# max32670 register map
Vendor: Maxim-Integrated; Series: ARMCM4; File version: 1.1
CPU: CM4 r2p1, little endian, MPU, FPU, 3 interrupt priority bits
Registers are 32-bit, read-write, reset 0x0 unless marked. A register's access mark holds for its fields unless they carry their own. Offsets are from the block's base; [hi:lo] are bit positions.

## I2S — Inter-IC Sound Interface.
Base 0x40060000
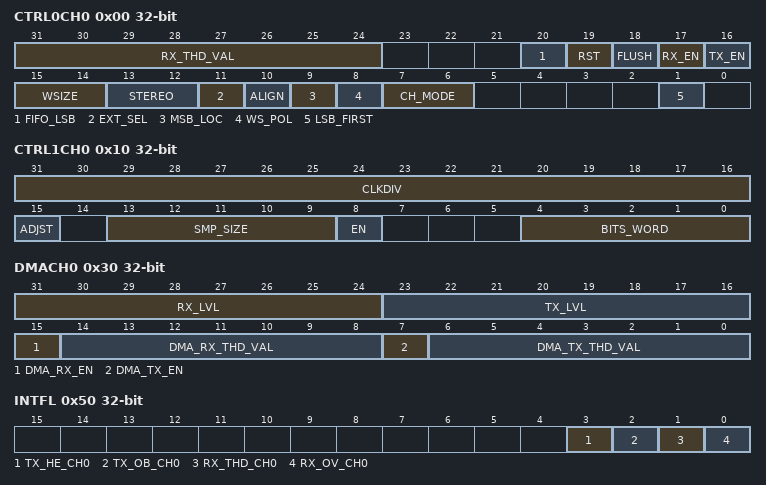
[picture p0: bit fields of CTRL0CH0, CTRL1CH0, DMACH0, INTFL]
0x00 CTRL0CH0 — Global mode channel.
  [31:24] RX_THD_VAL — depth of receive FIFO for threshold interrupt generation.
  [20] FIFO_LSB — Bit Field Control.
  [19] RST — Write 1 to reset channel.
  [18] FLUSH — Flushes the TX/RX FIFO buffer.
  [17] RX_EN — RX channel enable.
  [16] TX_EN — TX channel enable.
  [15:14] WSIZE — Data size when write to FIFO.
  [13:12] STEREO ro — Stereo mode of I2S.
  [11] EXT_SEL — External SCK/WS selection.
  [10] ALIGN ro — Align to MSB or LSB.
  [9] MSB_LOC ro — MSB location.
  [8] WS_POL — WS polarity select.
  [7:6] CH_MODE — SCK Select.
  [1] LSB_FIRST — LSB Transmit Receive First.
0x10 CTRL1CH0 — Local channel Setup.
  [31:16] CLKDIV — I2S clock frequency divisor.
  [15] ADJST — LSB/MSB Justify.
  [13:9] SMP_SIZE — I2S sample size length.
  [8] EN — I2S clock enable.
  [4:0] BITS_WORD — I2S word length.
0x30 DMACH0 — DMA Control.
  [31:24] RX_LVL — Number of data word in the RX FIFO.
  [23:16] TX_LVL — Number of data word in the TX FIFO.
  [15] DMA_RX_EN — RX DMA channel enable.
  [14:8] DMA_RX_THD_VAL — RX FIFO Level DMA Trigger.
  [7] DMA_TX_EN — TX DMA channel enable.
  [6:0] DMA_TX_THD_VAL — TX FIFO Level DMA Trigger.
0x40 FIFOCH0 — I2S Fifo.
  [31:0] DATA — Load/unload location for TX and RX FIFO buffers.
0x50 INTFL — ISR Status.
  [3] TX_HE_CH0 — Status for interrupt when TX FIFO is half empty.
  [2] TX_OB_CH0 — Status for interrupt when TX FIFO has only one byte remaining.
  [1] RX_THD_CH0 — Status for interrupt when RX FIFO reaches the number of bytes configured by the RXTHD field.
  [0] RX_OV_CH0 — Status for RX FIFO Overrun interrupt.
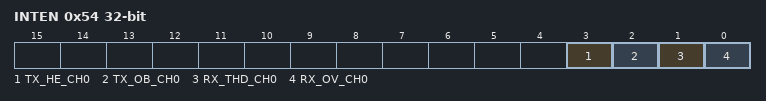
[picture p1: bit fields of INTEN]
0x54 INTEN — Interrupt Enable.
  [3] TX_HE_CH0 — Enable for interrupt when TX FIFO is half empty.
  [2] TX_OB_CH0 — Enable for interrupt when TX FIFO has only one byte remaining.
  [1] RX_THD_CH0 — Enable for interrupt when RX FIFO reaches the number of bytes configured by the RXTHD field.
  [0] RX_OV_CH0 — Enable for RX FIFO Overrun interrupt.
0x58 EXTSETUP — Ext Control.
  [4:0] EXT_BITS_WORD — Word Length for ch_mode.

## ICC0 — Instruction Cache Controller Registers
Base 0x4002A000
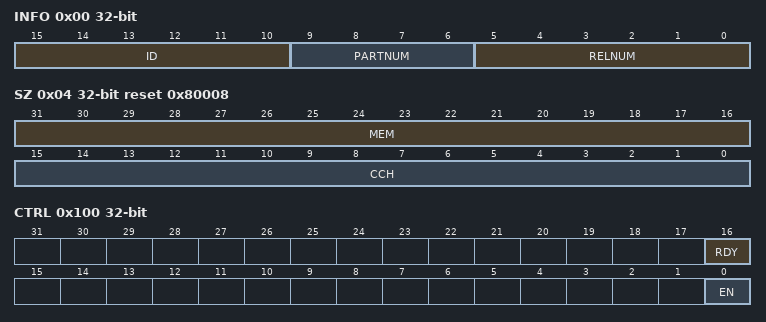
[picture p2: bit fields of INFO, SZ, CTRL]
0x00 INFO ro — Cache ID Register.
  [15:10] ID — Cache ID. This field reflects the value of the C_ID_CACHEID configuration parameter.
  [9:6] PARTNUM — Part Number. This field reflects the value of C_ID_PART_NUMBER configuration parameter.
  [5:0] RELNUM — Release Number. Identifies the RTL release version.
0x04 SZ ro reset 0x80008 — Memory Configuration Register.
  [31:16] MEM — Main Memory Size. Indicates the total size, in units of 128 Kbytes, of code memory accessible to the cache controller.
  [15:0] CCH — Cache Size. Indicates total size in Kbytes of cache.
0x100 CTRL — Cache Control and Status Register.
  [16] RDY ro — Cache Ready flag. Cleared by hardware when at any time the cache as a whole is invalidated (including a system reset). When this bit is 0, the cache is effectively in bypass mode (instruction fetches will come from main memory or from the line fill buffer). Set by hardware when the invalidate operation is complete and the cache is ready.
    0=notReady; 1=ready
  [0] EN — Cache Enable. Controls whether the cache is bypassed or is in use. Changing the state of this bit will cause the instruction cache to be flushed and its contents invalidated.
    0=dis (Cache Bypassed. Instruction data is stored in the line fill buffer but is not written to main cache memory array.); 1=en (Cache Enabled.)
0x700 INVALIDATE — Invalidate All Registers.
  [31:0] INVALID — Invalidate.

## MCR — Miscellaneous Control Registers.
Base 0x40106C00
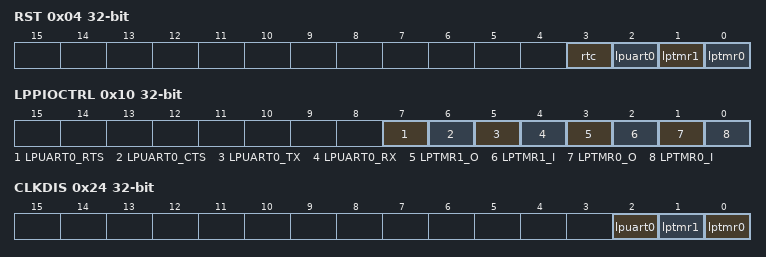
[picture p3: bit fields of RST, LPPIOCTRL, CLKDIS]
0x04 RST reset not defined — Reset control register 0.
  [3] rtc — Setting this bit will reset the Real-Time Clock.
    1=rst (Reset Real-Time Clock.)
  [2] lpuart0 — Setting this bit will reset LPUART0.
    1=rst (Reset LPUART0.)
  [1] lptmr1 — Setting this bit will reset LPTMR1.
    1=rst (Reset LPTMR1.)
  [0] lptmr0 — Setting this bit will reset LPTMR0.
    1=rst (Reset LPTMR0.)
0x10 LPPIOCTRL reset not defined — Low-power peripheral IO control.
  [7] LPUART0_RTS — Setting this bit will enable the low-power UART 0 (UART3) RTS pin while operating in low-power modes.
    0=dis (Disable LPUART0 RTS pin.); 1=en (Enable LPUART0 RTS pin.)
  [6] LPUART0_CTS — Setting this bit will enable the low-power UART 0 (UART3) CTS pin while operating in low-power modes.
    0=dis (Disable LPUART0 CTS pin.); 1=en (Enable LPUART0 CTS pin.)
  [5] LPUART0_TX — Setting this bit will enable the low-power UART 0 (UART3) TX pin while operating in low-power modes.
    0=dis (Disable LPUART0 TX pin.); 1=en (Enable LPUART0 TX pin.)
  [4] LPUART0_RX — Setting this bit will enable the low-power UART 0 (UART3) RX pin while operating in low-power modes.
    0=dis (Disable LPUART0 RX pin.); 1=en (Enable LPUART0 RX pin.)
  [3] LPTMR1_O — Setting this bit will enable the low-power timer 1 (timer 5) output pin while operating in low-power modes.
    0=dis (Disable LPTMR1 output pin.); 1=en (Enable LPTMR1 output pin.)
  [2] LPTMR1_I — Setting this bit will enable the low-power timer 1 (timer 5) input pin while operating in low-power modes.
    0=dis (Disable LPTMR1 input pin.); 1=en (Enable LPTMR1 input pin.)
  [1] LPTMR0_O — Setting this bit will enable the low-power timer 0 (timer 4) output pin while operating in low-power modes.
    0=dis (Disable LPTMR0 output pin.); 1=en (Enable LPTMR0 output pin.)
  [0] LPTMR0_I — Setting this bit will enable the low-power timer 0 (timer 4) input pin while operating in low-power modes.
    0=dis (Disable LPTMR0 input pin.); 1=en (Enable LPTMR0 input pin.)
0x24 CLKDIS — Peripheral clock control register.
  [2] lpuart0 — Clearing this bit will enable the low-power UART 0 (UART3) peripheral clock.
    0=en (Enable LPUART0 clock.); 1=dis (Disable LPUART0 clock.)
  [1] lptmr1 — Clearing this bit will enable the low-power timer 1 (timer 5) peripheral clock.
    0=en (Enable LPTMR1 clock.); 1=dis (Disable LPTMR1 clock.)
  [0] lptmr0 — Clearing this bit will enable the low-power timer 0 (timer 4) peripheral clock.
    0=en (Enable LPTMR0 clock.); 1=dis (Disable LPTMR0 clock.)
